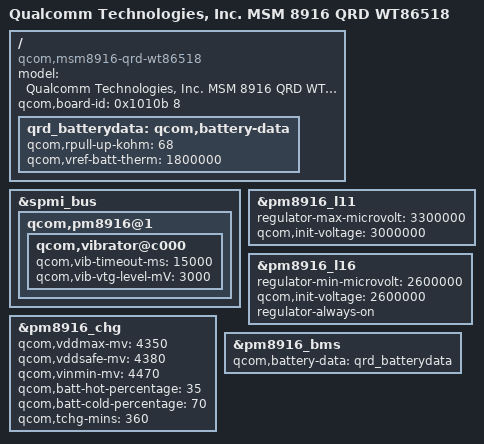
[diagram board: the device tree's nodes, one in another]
/* Copyright (c) 2014, The Linux Foundation. All rights reserved.
 *
 * This program is free software; you can redistribute it and/or modify
 * it under the terms of the GNU General Public License version 2 and
 * only version 2 as published by the Free Software Foundation.
 *
 * This program is distributed in the hope that it will be useful,
 * but WITHOUT ANY WARRANTY; without even the implied warranty of
 * MERCHANTABILITY or FITNESS FOR A PARTICULAR PURPOSE.  See the
 * GNU General Public License for more details.
 */

/dts-v1/;

#include "msm8916-qrd.dtsi"
#include "msm8916-memory.dtsi"
#include "wt86518/msm8916-wt86518.dtsi"

/ {
	model = "Qualcomm Technologies, Inc. MSM 8916 QRD WT86518";
	compatible = "qcom,msm8916-qrd-wt86518", "qcom,msm8916-qrd", "qcom,msm8916", "qcom,qrd";
	qcom,board-id = <0x1010b 8>;          
                                                                

};

&spmi_bus {
	qcom,pm8916@1 {
		qcom,vibrator@c000 {
			status = "okay";
			qcom,vib-timeout-ms = <15000>;
			qcom,vib-vtg-level-mV = <3000>;
		};
	};
};

&pm8916_l11 {
	regulator-max-microvolt = <3300000>;
	qcom,init-voltage = <3000000>;
};

&pm8916_l16 {
	regulator-min-microvolt = <2600000>;
	qcom,init-voltage = <2600000>;
	regulator-always-on;
};

&pm8916_chg {
	qcom,vddmax-mv = <4350>;
	qcom,vddsafe-mv = <4380>;
	qcom,vinmin-mv = <4470>;
	qcom,batt-hot-percentage = <35>;
	qcom,batt-cold-percentage = <70>;
	qcom,tchg-mins = <360>;
	status = "okay";
};

/ {
	qrd_batterydata: qcom,battery-data {
		qcom,rpull-up-kohm = <68>;
		qcom,vref-batt-therm = <1800000>;

		#include "wt86518/batterydata-wingtech-guangyu-4v35-2300mah.dtsi"
	};
};

&pm8916_bms {
	status = "ok";
	qcom,battery-data = <&qrd_batterydata>;
};                                                                                             
                                                                                           
